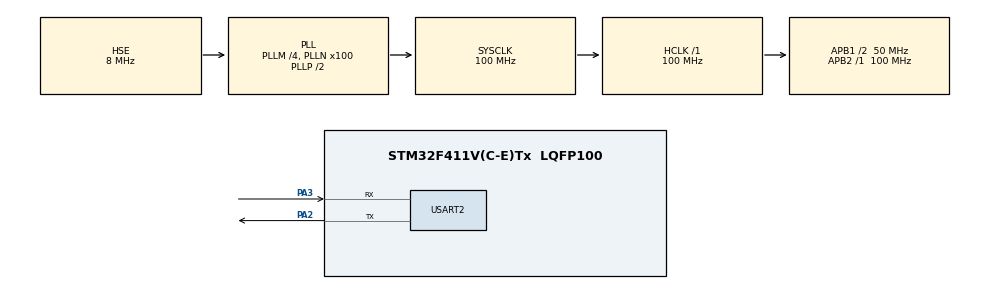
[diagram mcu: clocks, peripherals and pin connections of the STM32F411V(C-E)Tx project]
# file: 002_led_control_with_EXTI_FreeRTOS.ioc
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FREERTOS.Tasks01=readButtonState,27,128,readButtonStateTask,Default,NULL,Dynamic,NULL,NULL;ledFlashh,27,128,ledFlashTask,Default,NULL,Dynamic,NULL,NULL
Mcu.Family=STM32F4
Mcu.Name=STM32F411V(C-E)Tx
Mcu.Package=LQFP100
NVIC.PriorityGroup=NVIC_PRIORITYGROUP_4
NVIC.USART2_IRQn=true\:5\:0\:false\:false\:true\:true\:true\:true\:true
PA2.Mode=Asynchronous
PA2.Signal=USART2_TX
PA3.Mode=Asynchronous
PA3.Signal=USART2_RX
PH0\ -\ OSC_IN.Mode=HSE-External-Oscillator
PH0\ -\ OSC_IN.Signal=RCC_OSC_IN
PH1\ -\ OSC_OUT.Mode=HSE-External-Oscillator
PH1\ -\ OSC_OUT.Signal=RCC_OSC_OUT
ProjectManager.HeapSize=0x200
ProjectManager.StackSize=0x400
ProjectManager.TargetToolchain=STM32CubeIDE
RCC.48MHZClocksFreq_Value=50000000
RCC.AHBFreq_Value=100000000
RCC.APB1CLKDivider=RCC_HCLK_DIV2
RCC.APB1Freq_Value=50000000
RCC.APB1TimFreq_Value=100000000
RCC.APB2Freq_Value=100000000
RCC.APB2TimFreq_Value=100000000
RCC.CortexFreq_Value=100000000
RCC.HCLKFreq_Value=100000000
RCC.HSE_VALUE=8000000
RCC.HSI_VALUE=16000000
RCC.LSE_VALUE=32768
RCC.PLLM=4
RCC.PLLN=100
RCC.PLLSourceVirtual=RCC_PLLSOURCE_HSE
RCC.SYSCLKFreq_VALUE=100000000
RCC.SYSCLKSource=RCC_SYSCLKSOURCE_PLLCLK
RCC.VCOOutputFreq_Value=200000000
USART2.VirtualMode=VM_ASYNC
VP_FREERTOS_VS_CMSIS_V2.Mode=CMSIS_V2
board=custom

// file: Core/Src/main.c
/* USER CODE BEGIN Header */
/**
 ******************************************************************************
 * @file           : main.c
 * @brief          : Main program body
 ******************************************************************************
 * @attention
 *
 * Copyright (c) 2023 STMicroelectronics.
 * All rights reserved.
 *
 * This software is licensed under terms that can be found in the LICENSE file
 * in the root directory of this software component.
 * If no LICENSE file comes with this software, it is provided AS-IS.
 *
 ******************************************************************************
 */
/* USER CODE END Header */
#include "main.h"
#include "cmsis_os.h"

/* USER CODE BEGIN Includes */
#include "user_led.h"
#include "user_button_EXTI.h"
/* USER CODE END Includes */

UART_HandleTypeDef huart2;

/* Definitions for ledFlashh */
osThreadId_t ledFlashhHandle;
const osThreadAttr_t ledFlashh_attributes = { .name = "ledFlashh", .stack_size =
		128 * 4, .priority = (osPriority_t) osPriorityNormal3, };

void SystemClock_Config(void);
static void MX_GPIO_Init(void);
static void MX_USART2_UART_Init(void);
void button_exti_init(void);
void ledFlashTask(void *argument);
void ButtonHandler(void);

/* USER CODE BEGIN 0 */
uint8_t buttonCount = 0;
/* USER CODE END 0 */

int main(void) {
	/* USER CODE BEGIN 1 */
	user_led_init();
	user_button_EXTI_init();
	/* USER CODE END 1 */

	/* MCU Configuration--------------------------------------------------------*/

	/* Reset of all peripherals, Initializes the Flash interface and the Systick. */
	HAL_Init();

	/* Configure the system clock */
	SystemClock_Config();

	/* Initialize all configured peripherals */
	MX_GPIO_Init();
	MX_USART2_UART_Init();

	/* Init scheduler */
	osKernelInitialize();

	/* Create the thread(s) */
	/* creation of ledFlashh */
	ledFlashhHandle = osThreadNew(ledFlashTask, NULL,
			&ledFlashh_attributes);

	/* Start scheduler */
	osKernelStart();

	/* We should never get here as control is now taken by the scheduler */
	/* Infinite loop */
	while (1) {

	}
}

void SystemClock_Config(void) {
	RCC_OscInitTypeDef RCC_OscInitStruct = { 0 };
	RCC_ClkInitTypeDef RCC_ClkInitStruct = { 0 };

	/** Configure the main internal regulator output voltage
	 */
	__HAL_RCC_PWR_CLK_ENABLE();
	__HAL_PWR_VOLTAGESCALING_CONFIG(PWR_REGULATOR_VOLTAGE_SCALE1);

	/** Initializes the RCC Oscillators according to the specified parameters
	 * in the RCC_OscInitTypeDef structure.
	 */
	RCC_OscInitStruct.OscillatorType = RCC_OSCILLATORTYPE_HSE;
	RCC_OscInitStruct.HSEState = RCC_HSE_ON;
	RCC_OscInitStruct.PLL.PLLState = RCC_PLL_ON;
	RCC_OscInitStruct.PLL.PLLSource = RCC_PLLSOURCE_HSE;
	RCC_OscInitStruct.PLL.PLLM = 4;
	RCC_OscInitStruct.PLL.PLLN = 100;
	RCC_OscInitStruct.PLL.PLLP = RCC_PLLP_DIV2;
	RCC_OscInitStruct.PLL.PLLQ = 4;
	if (HAL_RCC_OscConfig(&RCC_OscInitStruct) != HAL_OK) {
		Error_Handler();
	}

	/** Initializes the CPU, AHB and APB buses clocks
	 */
	RCC_ClkInitStruct.ClockType = RCC_CLOCKTYPE_HCLK | RCC_CLOCKTYPE_SYSCLK
			| RCC_CLOCKTYPE_PCLK1 | RCC_CLOCKTYPE_PCLK2;
	RCC_ClkInitStruct.SYSCLKSource = RCC_SYSCLKSOURCE_PLLCLK;
	RCC_ClkInitStruct.AHBCLKDivider = RCC_SYSCLK_DIV1;
	RCC_ClkInitStruct.APB1CLKDivider = RCC_HCLK_DIV2;
	RCC_ClkInitStruct.APB2CLKDivider = RCC_HCLK_DIV1;

	if (HAL_RCC_ClockConfig(&RCC_ClkInitStruct, FLASH_LATENCY_3) != HAL_OK) {
		Error_Handler();
	}
}

static void MX_USART2_UART_Init(void) {

	huart2.Instance = USART2;
	huart2.Init.BaudRate = 115200;
	huart2.Init.WordLength = UART_WORDLENGTH_8B;
	huart2.Init.StopBits = UART_STOPBITS_1;
	huart2.Init.Parity = UART_PARITY_NONE;
	huart2.Init.Mode = UART_MODE_TX_RX;
	huart2.Init.HwFlowCtl = UART_HWCONTROL_NONE;
	huart2.Init.OverSampling = UART_OVERSAMPLING_16;
	if (HAL_UART_Init(&huart2) != HAL_OK) {
		Error_Handler();
	}

}

static void MX_GPIO_Init(void) {

	/* GPIO Ports Clock Enable */
	__HAL_RCC_GPIOH_CLK_ENABLE();
	__HAL_RCC_GPIOA_CLK_ENABLE();

}

/* USER CODE BEGIN 4 */
void EXTI0_IRQHandler(void){

   if((EXTI->PR &EXTI_PR_PR0) == EXTI_PR_PR0){
	   EXTI->PR |= EXTI_PR_PR0;
	   ButtonHandler();
   }
}
void ButtonHandler(void){
	buttonCount++;
	if(buttonCount ==5){
		buttonCount =0;
	}
}
/* USER CODE END 4 */

/* USER CODE END Header_ledFlashTask */
void ledFlashTask(void *argument) {
	/* USER CODE BEGIN ledFlashTask */
	/* Infinite loop */
	for (;;) {
		if (buttonCount == 0) { // butun ledleri sondur
			for (int i = 12; i < 16; i++) {
				user_led_off(i);
			}

		} else if (buttonCount == 1) { // ledleri 1 saniye yak sondur
			for (int i = 12; i < 16; i++) {
				user_led_toggle(i);
			}
			vTaskDelay(1000);
		} else if (buttonCount == 2) { // ledleri 750 ms yak sondur
			for (int i = 12; i < 16; i++) {
				user_led_toggle(i);
			}
			vTaskDelay(750);
		} else if (buttonCount == 3) { // ledleri 500 saniye yak sondur
			for (int i = 12; i < 16; i++) {
				user_led_toggle(i);
			}
			vTaskDelay(500);
		} else if (buttonCount == 4) { // ledleri 250 ms yak sondur
			for (int i = 12; i < 16; i++) {
				user_led_toggle(i);
			}
			vTaskDelay(250);
		}
	}
	/* USER CODE END ledFlashTask */
}

void Error_Handler(void) {
	__disable_irq();
	while (1) {
	}
}
